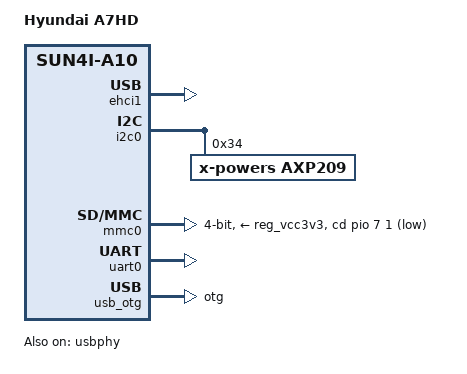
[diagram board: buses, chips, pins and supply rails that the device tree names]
/dts-v1/;
#include "sun4i-a10.dtsi"
#include "sunxi-common-regulators.dtsi"
#include <dt-bindings/gpio/gpio.h>
/ {
	model = "Hyundai A7HD";
	compatible = "hyundai,a7hd", "allwinner,sun4i-a10";
	aliases {
		serial0 = &uart0;
	};
	chosen {
		stdout-path = "serial0:115200n8";
	};
};
&ehci1 {
	status = "okay";
};
&i2c0 {
	status = "okay";
	axp209: pmic@34 {
		compatible = "x-powers,axp209";
		reg = <0x34>;
		interrupts = <0>;
		interrupt-controller;
		#interrupt-cells = <1>;
	};
};
&mmc0 {
	vmmc-supply = <&reg_vcc3v3>;
	bus-width = <4>;
	cd-gpios = <&pio 7 1 GPIO_ACTIVE_LOW>;  
	status = "okay";
};
&otg_sram {
	status = "okay";
};
&reg_usb0_vbus {
	status = "okay";
};
&reg_usb2_vbus {
	gpio = <&pio 7 6 GPIO_ACTIVE_HIGH>;  
	status = "okay";
};
&uart0 {
	pinctrl-names = "default";
	pinctrl-0 = <&uart0_pb_pins>;
	status = "okay";
};
&usb_otg {
	dr_mode = "otg";
	status = "okay";
};
&usbphy {
	usb0_id_det-gpios = <&pio 7 4 (GPIO_ACTIVE_HIGH | GPIO_PULL_UP)>;  
	usb0_vbus_det-gpios = <&pio 7 5 (GPIO_ACTIVE_HIGH | GPIO_PULL_DOWN)>;  
	usb0_vbus-supply = <&reg_usb0_vbus>;
	usb2_vbus-supply = <&reg_usb2_vbus>;
	status = "okay";
};
